# FOMU register map
Vendor: Foosn
Registers are 8-bit, read-write, reset 0x0 unless marked. A register's access mark holds for its fields unless they carry their own. Offsets are from the block's base; [hi:lo] are bit positions.

## USB
Base 0xE0004800
0x00 PULLUP_OUT
  [0] pullup_out
0x04 ADDRESS — Sets the USB device address, in order to ignore packets going to other devices on the bus. This value is reset when the host issues a USB Device Reset condition.
  [6:0] addr — Write the USB address from USB ``SET_ADDRESS`` packets.
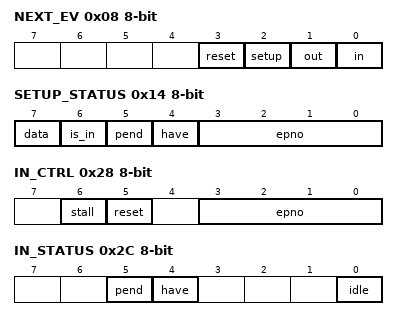
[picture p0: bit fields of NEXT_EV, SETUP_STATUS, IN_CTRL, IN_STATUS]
0x08 NEXT_EV ro — In ``eptri``, there are three endpoints. It is possible for an IRQ to fire and have all three bits set. Under these circumstances it can be difficult to know which event to process first. Use this register to determine which event needs to be processed first. Only one bit will ever be set at a time.
  [3] reset — ``1`` if the next event is a ``RESET`` event
  [2] setup — ``1`` if the next event is an ``SETUP`` event
  [1] out — ``1`` if the next event is an ``OUT`` event
  [0] in — ``1`` if the next event is an ``IN`` event
0x0C SETUP_DATA ro — Data from the last ``SETUP`` transactions. It will be 10 bytes long, because it will include the CRC16. This is a FIFO, and the queue is advanced automatically.
  [7:0] data — The next byte of ``SETUP`` data
0x10 SETUP_CTRL — Controls for managing how to handle ``SETUP`` transactions.
  [5] reset — Write a ``1`` here to reset the `SETUP` handler.
0x14 SETUP_STATUS ro — Status about the most recent ``SETUP`` transactions, and the state of the FIFO.
  [7] data — ``1`` if a DATA stage is expected.
  [6] is_in — ``1`` if an IN stage was detected.
  [5] pend — ``1`` if there is an IRQ pending.
  [4] have — ``1`` if there is data in the FIFO.
  [3:0] epno — The destination endpoint for the most recent SETUP token.
0x18 SETUP_EV_STATUS
  [1:0] setup_ev_status
0x1C SETUP_EV_PENDING
  [1:0] setup_ev_pending
0x20 SETUP_EV_ENABLE
  [1:0] setup_ev_enable
0x24 IN_DATA — Each byte written into this register gets added to an outgoing FIFO. Any bytes that are written here will be transmitted in the order in which they were added. The FIFO queue is automatically advanced with each write. The FIFO queue is 64 bytes deep. If you exceed this amount, the result is undefined.
  [7:0] data — The next byte to add to the queue.
0x28 IN_CTRL — Enables transmission of data in response to ``IN`` tokens, or resets the contents of the FIFO.
  [6] stall — Write a ``1`` here to stall the EP written in ``EP``.
  [5] reset — Write a ``1`` here to clear the contents of the FIFO.
  [3:0] epno — The endpoint number for the transaction that is queued in the FIFO.
0x2C IN_STATUS ro — Status about the IN handler. As soon as you write to `IN_DATA`, ``IN_STATUS.HAVE`` should go to ``1``.
  [5] pend — ``1`` if there is an IRQ pending.
  [4] have — This value is ``0`` if the FIFO is empty.
  [0] idle — This value is ``1`` if the packet has finished transmitting.
0x30 IN_EV_STATUS
  [0] in_ev_status
0x34 IN_EV_PENDING
  [0] in_ev_pending
0x38 IN_EV_ENABLE
  [0] in_ev_enable
0x3C OUT_DATA ro — Data received from the host will go into a FIFO. This register reflects the contents of the top byte in that FIFO. Reading from this register advances the FIFO pointer.
  [7:0] data — The top byte of the receive FIFO.
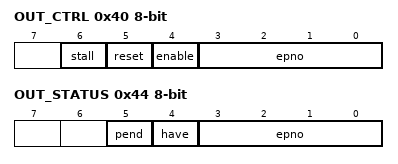
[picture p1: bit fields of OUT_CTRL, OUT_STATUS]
0x40 OUT_CTRL — Controls for receiving packet data. To enable an endpoint, write its value to ``epno``, with the ``enable`` bit set to ``1`` to enable an endpoint, or ``0`` to disable it. Resetting the OutHandler will set all ``enable`` bits to 0. Similarly, you can adjust the ``STALL`` state by setting or clearing the ``stall`` bit.
  [6] stall — Write a ``1`` here to stall an endpoint
  [5] reset — Write a ``1`` here to reset the ``OUT`` handler
  [4] enable — Write a ``1`` here to enable receiving data
  [3:0] epno — The endpoint number to update the ``enable`` and ``status`` bits for.
0x44 OUT_STATUS ro — Status about the current state of the `OUT` endpoint.
  [5] pend — ``1`` if there is an IRQ pending.
  [4] have — ``1`` if there is data in the FIFO.
  [3:0] epno — The destination endpoint for the most recent ``OUT`` packet.
0x48 OUT_EV_STATUS
  [0] out_ev_status
0x4C OUT_EV_PENDING
  [0] out_ev_pending
0x50 OUT_EV_ENABLE
  [0] out_ev_enable

## TIMER0
Base 0xE0002800
0x00 LOAD3 — Bits 24-31 of `TIMER0_LOAD`. Load value when Timer is (re-)enabled.In One-Shot mode, the value written to this register specify the Timer's duration in clock cycles.
  [7:0] load
0x04 LOAD2 — Bits 16-23 of `TIMER0_LOAD`.
  [7:0] load
0x08 LOAD1 — Bits 8-15 of `TIMER0_LOAD`.
  [7:0] load
0x0C LOAD0 — Bits 0-7 of `TIMER0_LOAD`.
  [7:0] load
0x10 RELOAD3 — Bits 24-31 of `TIMER0_RELOAD`. Reload value when Timer reaches 0.In Periodic mode, the value written to this register specify the Timer's period in clock cycles.
  [7:0] reload
0x14 RELOAD2 — Bits 16-23 of `TIMER0_RELOAD`.
  [7:0] reload
0x18 RELOAD1 — Bits 8-15 of `TIMER0_RELOAD`.
  [7:0] reload
0x1C RELOAD0 — Bits 0-7 of `TIMER0_RELOAD`.
  [7:0] reload
0x20 EN — Enable of the Timer.Set if to 1 to enable/start the Timer and 0 to disable the Timer
  [0] en
0x24 UPDATE_VALUE — Update of the current countdown value.A write to this register latches the current countdown value to `value` register.
  [0] update_value
0x28 VALUE3 ro — Bits 24-31 of `TIMER0_VALUE`. Latched countdown value
  [7:0] value
0x2C VALUE2 ro — Bits 16-23 of `TIMER0_VALUE`.
  [7:0] value
0x30 VALUE1 ro — Bits 8-15 of `TIMER0_VALUE`.
  [7:0] value
0x34 VALUE0 ro — Bits 0-7 of `TIMER0_VALUE`.
  [7:0] value
0x38 EV_STATUS
  [0] status
0x3C EV_PENDING
  [0] pending
0x40 EV_ENABLE
  [0] enable

## TOUCH
Base 0xE0005800
0x00 O — Output values for pads 1-4
  [3:0] o
0x04 OE — Output enable control for pads 1-4
  [3:0] oe
0x08 I ro — Input value for pads 1-4
  [3:0] i

## VERSION
Base 0xE0007000
0x00 MAJOR ro reset 0x2 — Major git tag version. For example, this firmware was built from git tag ``v2.0.3``, so this value is ``2``.
0x04 MINOR ro — Minor git tag version. For example, this firmware was built from git tag ``v2.0.3``, so this value is ``0``.
0x08 REVISION ro reset 0x3 — Revision git tag version. For example, this firmware was built from git tag ``v2.0.3``, so this value is ``3``.
0x0C GITREV3 ro — Bits 24-31 of `VERSION_GITREV`. First 32-bits of the git revision. This documentation was built from git rev ``00000000``, so this value is 0, which should be enough to check out the exact git version used to build this firmware.
  [7:0] gitrev
0x10 GITREV2 ro — Bits 16-23 of `VERSION_GITREV`.
  [7:0] gitrev
0x14 GITREV1 ro — Bits 8-15 of `VERSION_GITREV`.
  [7:0] gitrev
0x18 GITREV0 ro — Bits 0-7 of `VERSION_GITREV`.
  [7:0] gitrev
0x1C GITEXTRA1 ro — Bits 8-9 of `VERSION_GITEXTRA`. The number of additional commits beyond the git tag. For example, if this value is ``1``, then the repository this was built from has one additional commit beyond the tag indicated in `MAJOR`, `MINOR`, and `REVISION`.
  [7:0] gitextra
0x20 GITEXTRA0 ro reset 0x1 — Bits 0-7 of `VERSION_GITEXTRA`.
  [7:0] gitextra
0x24 DIRTY ro reset 0x1
  [0] dirty — Set to ``1`` if this device was built from a git repo with uncommitted modifications.
0x28 MODEL ro reset 0x50
  [7:0] model — Contains information on which model device this was built for.
0x2C SEED3 ro — Bits 24-31 of `VERSION_SEED`. 32-bit seed used for the place-and-route.
  [7:0] seed
0x30 SEED2 ro — Bits 16-23 of `VERSION_SEED`.
  [7:0] seed
0x34 SEED1 ro — Bits 8-15 of `VERSION_SEED`.
  [7:0] seed
0x38 SEED0 ro — Bits 0-7 of `VERSION_SEED`.
  [7:0] seed
